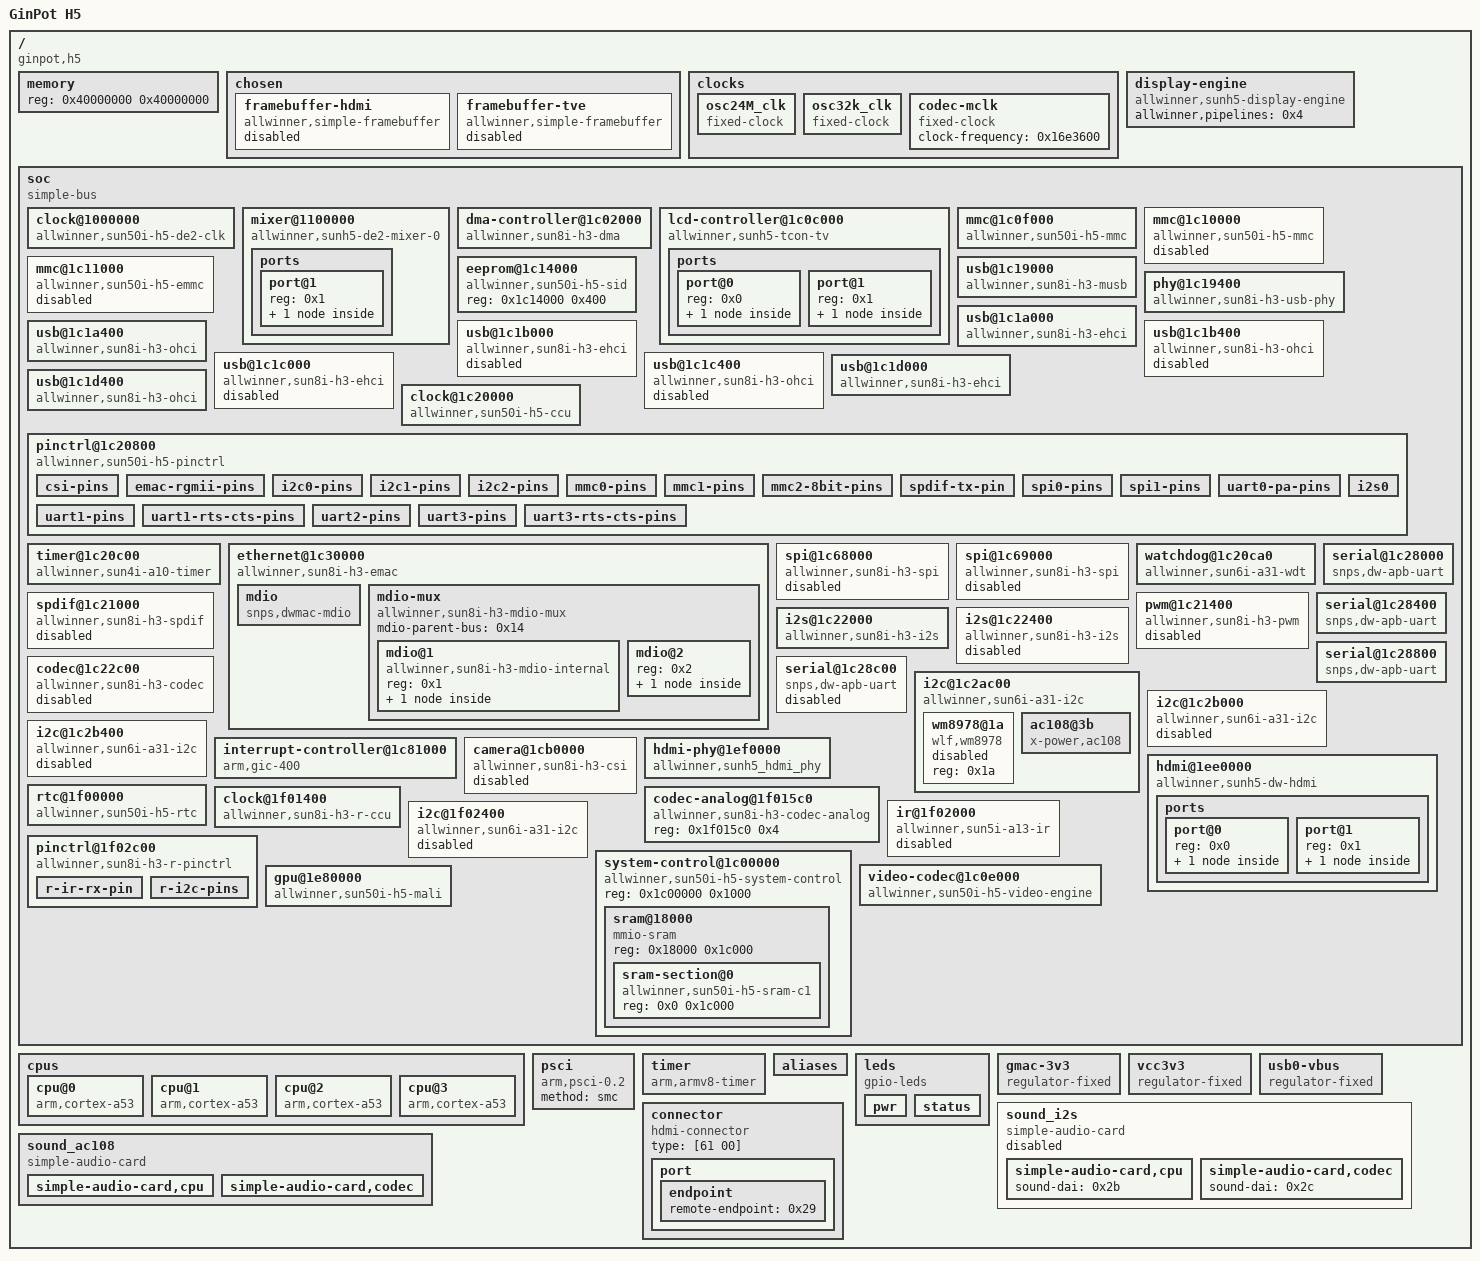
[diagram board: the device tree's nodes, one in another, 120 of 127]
/dts-v1/;

/ {
	serial-number = "82800001872ec2e4";
	interrupt-parent = <0x1>;
	#address-cells = <0x1>;
	#size-cells = <0x1>;
	model = "GinPot H5";
	compatible = "ginpot,h5", "allwinner,sun50i-h5";

	memory {
		reg = <0x40000000 0x40000000>;
		device_type = "memory";
	};

	chosen {
		linux,stdout-path = "/soc@01c00000/serial@01c28000:115200";
		bootargs = "console=ttyS0,115200 earlyprintk root=/dev/mmcblk0p2 rootfstype=ext4 rw rootwait panic=10 snd_soc_ac108.dyndbg=+p ac108_card.dyndbg=+p sunh5_drm.dyndbg=+p sunh5_mixer.dyndbg=+p sunh5_tcon.dyndbg=+p sunh5_drm_hdmi.dyndbg=+p";
		#address-cells = <0x1>;
		#size-cells = <0x1>;
		ranges;
		stdout-path = "serial0:115200n8";

		framebuffer-hdmi {
			compatible = "allwinner,simple-framebuffer", "simple-framebuffer";
			allwinner,pipeline = "mixer0-lcd0-hdmi";
			clocks = <0x2 0x6 0x3 0x66 0x3 0x6f>;
			status = "disabled";
		};

		framebuffer-tve {
			compatible = "allwinner,simple-framebuffer", "simple-framebuffer";
			allwinner,pipeline = "mixer1-lcd1-tve";
			clocks = <0x2 0x7 0x3 0x67>;
			status = "disabled";
		};
	};

	clocks {
		#address-cells = <0x1>;
		#size-cells = <0x1>;
		ranges;

		osc24M_clk {
			#clock-cells = <0x0>;
			compatible = "fixed-clock";
			clock-frequency = <0x16e3600>;
			clock-accuracy = <0xc350>;
			clock-output-names = "osc24M";
			phandle = <0xe>;
		};

		osc32k_clk {
			#clock-cells = <0x0>;
			compatible = "fixed-clock";
			clock-frequency = <0x8000>;
			clock-accuracy = <0xc350>;
			clock-output-names = "ext_osc32k";
			phandle = <0x24>;
		};

		codec-mclk {
			compatible = "fixed-clock";
			#clock-cells = <0x0>;
			clock-frequency = <0x16e3600>;
			phandle = <0x2f>;
		};
	};

	display-engine {
		compatible = "allwinner,sunh5-display-engine";
		allwinner,pipelines = <0x4>;
		status = "okay";
	};

	soc {
		compatible = "simple-bus";
		#address-cells = <0x1>;
		#size-cells = <0x1>;
		ranges;

		clock@1000000 {
			reg = <0x1000000 0x100000>;
			clocks = <0x3 0x65 0x3 0x30>;
			clock-names = "mod", "bus";
			resets = <0x3 0x22>;
			#clock-cells = <0x1>;
			#reset-cells = <0x1>;
			compatible = "allwinner,sun50i-h5-de2-clk";
			phandle = <0x2>;
		};

		mixer@1100000 {
			compatible = "allwinner,sunh5-de2-mixer-0";
			reg = <0x1100000 0x100000>;
			clocks = <0x2 0x0 0x2 0x6>;
			clock-names = "bus", "mod";
			resets = <0x2 0x0>;
			status = "okay";
			phandle = <0x4>;

			ports {
				#address-cells = <0x1>;
				#size-cells = <0x0>;

				port@1 {
					reg = <0x1>;

					endpoint {
						remote-endpoint = <0x5>;
						phandle = <0x6>;
					};
				};
			};
		};

		dma-controller@1c02000 {
			compatible = "allwinner,sun8i-h3-dma";
			reg = <0x1c02000 0x1000>;
			interrupts = <0x0 0x32 0x4>;
			clocks = <0x3 0x15>;
			resets = <0x3 0x6>;
			#dma-cells = <0x1>;
			phandle = <0x15>;
		};

		lcd-controller@1c0c000 {
			compatible = "allwinner,sunh5-tcon-tv";
			reg = <0x1c0c000 0x1000>;
			interrupts = <0x0 0x56 0x4>;
			clocks = <0x3 0x2a 0x3 0x66>;
			clock-names = "ahb", "tcon-ch1";
			resets = <0x3 0x1b>;
			reset-names = "lcd";
			status = "okay";

			ports {
				#address-cells = <0x1>;
				#size-cells = <0x0>;

				port@0 {
					reg = <0x0>;

					endpoint {
						remote-endpoint = <0x6>;
						phandle = <0x5>;
					};
				};

				port@1 {
					#address-cells = <0x1>;
					#size-cells = <0x0>;
					reg = <0x1>;

					endpoint@1 {
						reg = <0x1>;
						remote-endpoint = <0x7>;
						phandle = <0x22>;
					};
				};
			};
		};

		mmc@1c0f000 {
			reg = <0x1c0f000 0x1000>;
			pinctrl-names = "default";
			pinctrl-0 = <0x8>;
			resets = <0x3 0x7>;
			reset-names = "ahb";
			interrupts = <0x0 0x3c 0x4>;
			status = "okay";
			#address-cells = <0x1>;
			#size-cells = <0x0>;
			compatible = "allwinner,sun50i-h5-mmc", "allwinner,sun50i-a64-mmc";
			clocks = <0x3 0x16 0x3 0x47>;
			clock-names = "ahb", "mmc";
			vmmc-supply = <0x9>;
			bus-width = <0x4>;
			cd-gpios = <0xa 0x5 0x6 0x1>;
		};

		mmc@1c10000 {
			reg = <0x1c10000 0x1000>;
			pinctrl-names = "default";
			pinctrl-0 = <0xb>;
			resets = <0x3 0x8>;
			reset-names = "ahb";
			interrupts = <0x0 0x3d 0x4>;
			status = "disabled";
			#address-cells = <0x1>;
			#size-cells = <0x0>;
			compatible = "allwinner,sun50i-h5-mmc", "allwinner,sun50i-a64-mmc";
			clocks = <0x3 0x17 0x3 0x4a>;
			clock-names = "ahb", "mmc";
		};

		mmc@1c11000 {
			reg = <0x1c11000 0x1000>;
			resets = <0x3 0x9>;
			reset-names = "ahb";
			interrupts = <0x0 0x3e 0x4>;
			status = "disabled";
			#address-cells = <0x1>;
			#size-cells = <0x0>;
			compatible = "allwinner,sun50i-h5-emmc", "allwinner,sun50i-a64-emmc";
			clocks = <0x3 0x18 0x3 0x4d>;
			clock-names = "ahb", "mmc";
		};

		eeprom@1c14000 {
			reg = <0x1c14000 0x400>;
			compatible = "allwinner,sun50i-h5-sid";
		};

		usb@1c19000 {
			compatible = "allwinner,sun8i-h3-musb";
			reg = <0x1c19000 0x400>;
			clocks = <0x3 0x20>;
			resets = <0x3 0x11>;
			interrupts = <0x0 0x47 0x4>;
			interrupt-names = "mc";
			phys = <0xc 0x0>;
			phy-names = "usb";
			extcon = <0xc 0x0>;
			dr_mode = "otg";
			status = "okay";
		};

		phy@1c19400 {
			compatible = "allwinner,sun8i-h3-usb-phy";
			reg = <0x1c19400 0x2c 0x1c1a800 0x4 0x1c1b800 0x4 0x1c1c800 0x4 0x1c1d800 0x4>;
			reg-names = "phy_ctrl", "pmu0", "pmu1", "pmu2", "pmu3";
			clocks = <0x3 0x58 0x3 0x59 0x3 0x5a 0x3 0x5b>;
			clock-names = "usb0_phy", "usb1_phy", "usb2_phy", "usb3_phy";
			resets = <0x3 0x0 0x3 0x1 0x3 0x2 0x3 0x3>;
			reset-names = "usb0_reset", "usb1_reset", "usb2_reset", "usb3_reset";
			status = "okay";
			#phy-cells = <0x1>;
			usb0_id_det-gpios = <0xa 0x6 0xc 0x0>;
			usb0_vbus-supply = <0xd>;
			phandle = <0xc>;
		};

		usb@1c1a000 {
			compatible = "allwinner,sun8i-h3-ehci", "generic-ehci";
			reg = <0x1c1a000 0x100>;
			interrupts = <0x0 0x48 0x4>;
			clocks = <0x3 0x21 0x3 0x25>;
			resets = <0x3 0x12 0x3 0x16>;
			status = "okay";
		};

		usb@1c1a400 {
			compatible = "allwinner,sun8i-h3-ohci", "generic-ohci";
			reg = <0x1c1a400 0x100>;
			interrupts = <0x0 0x49 0x4>;
			clocks = <0x3 0x21 0x3 0x25 0x3 0x5c>;
			resets = <0x3 0x12 0x3 0x16>;
			status = "okay";
		};

		usb@1c1b000 {
			compatible = "allwinner,sun8i-h3-ehci", "generic-ehci";
			reg = <0x1c1b000 0x100>;
			interrupts = <0x0 0x4a 0x4>;
			clocks = <0x3 0x22 0x3 0x26>;
			resets = <0x3 0x13 0x3 0x17>;
			phys = <0xc 0x1>;
			status = "disabled";
		};

		usb@1c1b400 {
			compatible = "allwinner,sun8i-h3-ohci", "generic-ohci";
			reg = <0x1c1b400 0x100>;
			interrupts = <0x0 0x4b 0x4>;
			clocks = <0x3 0x22 0x3 0x26 0x3 0x5d>;
			resets = <0x3 0x13 0x3 0x17>;
			phys = <0xc 0x1>;
			status = "disabled";
		};

		usb@1c1c000 {
			compatible = "allwinner,sun8i-h3-ehci", "generic-ehci";
			reg = <0x1c1c000 0x100>;
			interrupts = <0x0 0x4c 0x4>;
			clocks = <0x3 0x23 0x3 0x27>;
			resets = <0x3 0x14 0x3 0x18>;
			phys = <0xc 0x2>;
			status = "disabled";
		};

		usb@1c1c400 {
			compatible = "allwinner,sun8i-h3-ohci", "generic-ohci";
			reg = <0x1c1c400 0x100>;
			interrupts = <0x0 0x4d 0x4>;
			clocks = <0x3 0x23 0x3 0x27 0x3 0x5e>;
			resets = <0x3 0x14 0x3 0x18>;
			phys = <0xc 0x2>;
			status = "disabled";
		};

		usb@1c1d000 {
			compatible = "allwinner,sun8i-h3-ehci", "generic-ehci";
			reg = <0x1c1d000 0x100>;
			interrupts = <0x0 0x4e 0x4>;
			clocks = <0x3 0x24 0x3 0x28>;
			resets = <0x3 0x15 0x3 0x19>;
			phys = <0xc 0x3>;
			status = "okay";
		};

		usb@1c1d400 {
			compatible = "allwinner,sun8i-h3-ohci", "generic-ohci";
			reg = <0x1c1d400 0x100>;
			interrupts = <0x0 0x4f 0x4>;
			clocks = <0x3 0x24 0x3 0x28 0x3 0x5f>;
			resets = <0x3 0x15 0x3 0x19>;
			phys = <0xc 0x3>;
			status = "okay";
		};

		clock@1c20000 {
			reg = <0x1c20000 0x400>;
			clocks = <0xe 0xf 0x0>;
			clock-names = "hosc", "losc";
			#clock-cells = <0x1>;
			#reset-cells = <0x1>;
			compatible = "allwinner,sun50i-h5-ccu";
			phandle = <0x3>;
		};

		pinctrl@1c20800 {
			reg = <0x1c20800 0x400>;
			interrupts = <0x0 0xb 0x4 0x0 0x11 0x4 0x0 0x17 0x4>;
			clocks = <0x3 0x36 0xe 0xf 0x0>;
			clock-names = "apb", "hosc", "losc";
			gpio-controller;
			#gpio-cells = <0x3>;
			interrupt-controller;
			#interrupt-cells = <0x3>;
			compatible = "allwinner,sun50i-h5-pinctrl";
			phandle = <0xa>;

			csi-pins {
				pins = "PE0", "PE2", "PE3", "PE4", "PE5", "PE6", "PE7", "PE8", "PE9", "PE10", "PE11";
				function = "csi";
				phandle = <0x20>;
			};

			emac-rgmii-pins {
				pins = "PD0", "PD1", "PD2", "PD3", "PD4", "PD5", "PD7", "PD8", "PD9", "PD10", "PD12", "PD13", "PD15", "PD16", "PD17";
				function = "emac";
				drive-strength = <0x28>;
				phandle = <0x11>;
			};

			i2c0-pins {
				pins = "PA11", "PA12";
				function = "i2c0";
				phandle = <0x1d>;
			};

			i2c1-pins {
				pins = "PA18", "PA19";
				function = "i2c1";
				phandle = <0x1e>;
			};

			i2c2-pins {
				pins = "PE12", "PE13";
				function = "i2c2";
				phandle = <0x1f>;
			};

			mmc0-pins {
				pins = "PF0", "PF1", "PF2", "PF3", "PF4", "PF5";
				function = "mmc0";
				drive-strength = <0x1e>;
				bias-pull-up;
				phandle = <0x8>;
			};

			mmc1-pins {
				pins = "PG0", "PG1", "PG2", "PG3", "PG4", "PG5";
				function = "mmc1";
				drive-strength = <0x1e>;
				bias-pull-up;
				phandle = <0xb>;
			};

			mmc2-8bit-pins {
				pins = "PC5", "PC6", "PC8", "PC9", "PC10", "PC11", "PC12", "PC13", "PC14", "PC15", "PC16";
				function = "mmc2";
				drive-strength = <0x1e>;
				bias-pull-up;
			};

			spdif-tx-pin {
				pins = "PA17";
				function = "spdif";
			};

			spi0-pins {
				pins = "PC0", "PC1", "PC2", "PC3";
				function = "spi0";
				phandle = <0x16>;
			};

			spi1-pins {
				pins = "PA15", "PA16", "PA14", "PA13";
				function = "spi1";
				phandle = <0x17>;
			};

			uart0-pa-pins {
				pins = "PA4", "PA5";
				function = "uart0";
				phandle = <0x1a>;
			};

			uart1-pins {
				pins = "PG6", "PG7";
				function = "uart1";
				phandle = <0x1b>;
			};

			uart1-rts-cts-pins {
				pins = "PG8", "PG9";
				function = "uart1";
			};

			uart2-pins {
				pins = "PA0", "PA1";
				function = "uart2";
				phandle = <0x1c>;
			};

			uart3-pins {
				pins = "PA13", "PA14";
				function = "uart3";
			};

			uart3-rts-cts-pins {
				pins = "PA15", "PA16";
				function = "uart3";
			};

			i2s0 {
				pins = "PA18", "PA19", "PA20", "PA21";
				function = "i2s0";
				phandle = <0x18>;
			};
		};

		timer@1c20c00 {
			compatible = "allwinner,sun4i-a10-timer";
			reg = <0x1c20c00 0xa0>;
			interrupts = <0x0 0x12 0x4 0x0 0x13 0x4>;
			clocks = <0xe>;
		};

		ethernet@1c30000 {
			local-mac-address = [02 01 87 2e c2 e4];
			compatible = "allwinner,sun8i-h3-emac";
			syscon = <0x10>;
			reg = <0x1c30000 0x10000>;
			interrupts = <0x0 0x52 0x4>;
			interrupt-names = "macirq";
			resets = <0x3 0xc>;
			reset-names = "stmmaceth";
			clocks = <0x3 0x1b>;
			clock-names = "stmmaceth";
			status = "okay";
			pinctrl-names = "default";
			pinctrl-0 = <0x11>;
			phy-supply = <0x12>;
			phy-handle = <0x13>;
			phy-mode = "rgmii";

			mdio {
				#address-cells = <0x1>;
				#size-cells = <0x0>;
				compatible = "snps,dwmac-mdio";
				phandle = <0x14>;
			};

			mdio-mux {
				compatible = "allwinner,sun8i-h3-mdio-mux";
				#address-cells = <0x1>;
				#size-cells = <0x0>;
				mdio-parent-bus = <0x14>;

				mdio@1 {
					compatible = "allwinner,sun8i-h3-mdio-internal";
					reg = <0x1>;
					#address-cells = <0x1>;
					#size-cells = <0x0>;

					ethernet-phy@1 {
						compatible = "ethernet-phy-ieee802.3-c22";
						reg = <0x1>;
						clocks = <0x3 0x43>;
						resets = <0x3 0x27>;
					};
				};

				mdio@2 {
					reg = <0x2>;
					#address-cells = <0x1>;
					#size-cells = <0x0>;

					ethernet-phy@7 {
						compatible = "ethernet-phy-ieee802.3-c22";
						reg = <0x7>;
						phandle = <0x13>;
					};
				};
			};
		};

		spi@1c68000 {
			compatible = "allwinner,sun8i-h3-spi";
			reg = <0x1c68000 0x1000>;
			interrupts = <0x0 0x41 0x4>;
			clocks = <0x3 0x1e 0x3 0x52>;
			clock-names = "ahb", "mod";
			dmas = <0x15 0x17 0x15 0x17>;
			dma-names = "rx", "tx";
			pinctrl-names = "default";
			pinctrl-0 = <0x16>;
			resets = <0x3 0xf>;
			status = "disabled";
			#address-cells = <0x1>;
			#size-cells = <0x0>;
		};

		spi@1c69000 {
			compatible = "allwinner,sun8i-h3-spi";
			reg = <0x1c69000 0x1000>;
			interrupts = <0x0 0x42 0x4>;
			clocks = <0x3 0x1f 0x3 0x53>;
			clock-names = "ahb", "mod";
			dmas = <0x15 0x18 0x15 0x18>;
			dma-names = "rx", "tx";
			pinctrl-names = "default";
			pinctrl-0 = <0x17>;
			resets = <0x3 0x10>;
			status = "disabled";
			#address-cells = <0x1>;
			#size-cells = <0x0>;
		};

		watchdog@1c20ca0 {
			compatible = "allwinner,sun6i-a31-wdt";
			reg = <0x1c20ca0 0x20>;
			interrupts = <0x0 0x19 0x4>;
		};

		spdif@1c21000 {
			#sound-dai-cells = <0x0>;
			compatible = "allwinner,sun8i-h3-spdif";
			reg = <0x1c21000 0x400>;
			interrupts = <0x0 0xc 0x4>;
			clocks = <0x3 0x35 0x3 0x57>;
			resets = <0x3 0x29>;
			clock-names = "apb", "spdif";
			dmas = <0x15 0x2>;
			dma-names = "tx";
			status = "disabled";
		};

		pwm@1c21400 {
			compatible = "allwinner,sun8i-h3-pwm";
			reg = <0x1c21400 0x8>;
			clocks = <0xe>;
			#pwm-cells = <0x3>;
			status = "disabled";
		};

		i2s@1c22000 {
			#sound-dai-cells = <0x0>;
			compatible = "allwinner,sun8i-h3-i2s";
			reg = <0x1c22000 0x400>;
			interrupts = <0x0 0xd 0x4>;
			clocks = <0x3 0x38 0x3 0x54>;
			clock-names = "apb", "mod";
			dmas = <0x15 0x3 0x15 0x3>;
			resets = <0x3 0x2b>;
			dma-names = "rx", "tx";
			status = "okay";
			pinctrl-names = "default";
			pinctrl-0 = <0x18>;
			#address-cells = <0x1>;
			#size-cells = <0x0>;
			phandle = <0x2b>;
		};

		i2s@1c22400 {
			#sound-dai-cells = <0x0>;
			compatible = "allwinner,sun8i-h3-i2s";
			reg = <0x1c22400 0x400>;
			interrupts = <0x0 0xe 0x4>;
			clocks = <0x3 0x39 0x3 0x55>;
			clock-names = "apb", "mod";
			dmas = <0x15 0x4 0x15 0x4>;
			resets = <0x3 0x2c>;
			dma-names = "rx", "tx";
			status = "disabled";
		};

		codec@1c22c00 {
			#sound-dai-cells = <0x0>;
			compatible = "allwinner,sun8i-h3-codec";
			reg = <0x1c22c00 0x400>;
			interrupts = <0x0 0x1d 0x4>;
			clocks = <0x3 0x34 0x3 0x6d>;
			clock-names = "apb", "codec";
			resets = <0x3 0x28>;
			dmas = <0x15 0xf 0x15 0xf>;
			dma-names = "rx", "tx";
			allwinner,codec-analog-controls = <0x19>;
			status = "disabled";
			allwinner,audio-routing = "Line Out", "LINEOUT", "MIC1", "Mic", "Mic", "MBIAS";
		};

		serial@1c28000 {
			compatible = "snps,dw-apb-uart";
			reg = <0x1c28000 0x400>;
			interrupts = <0x0 0x0 0x4>;
			reg-shift = <0x2>;
			reg-io-width = <0x4>;
			clocks = <0x3 0x3e>;
			resets = <0x3 0x31>;
			dmas = <0x15 0x6 0x15 0x6>;
			dma-names = "rx", "tx";
			status = "okay";
			pinctrl-names = "default";
			pinctrl-0 = <0x1a>;
		};

		serial@1c28400 {
			compatible = "snps,dw-apb-uart";
			reg = <0x1c28400 0x400>;
			interrupts = <0x0 0x1 0x4>;
			reg-shift = <0x2>;
			reg-io-width = <0x4>;
			clocks = <0x3 0x3f>;
			resets = <0x3 0x32>;
			dmas = <0x15 0x7 0x15 0x7>;
			dma-names = "rx", "tx";
			status = "okay";
			pinctrl-names = "default";
			pinctrl-0 = <0x1b>;
		};

		serial@1c28800 {
			compatible = "snps,dw-apb-uart";
			reg = <0x1c28800 0x400>;
			interrupts = <0x0 0x2 0x4>;
			reg-shift = <0x2>;
			reg-io-width = <0x4>;
			clocks = <0x3 0x40>;
			resets = <0x3 0x33>;
			dmas = <0x15 0x8 0x15 0x8>;
			dma-names = "rx", "tx";
			status = "okay";
			pinctrl-names = "default";
			pinctrl-0 = <0x1c>;
		};

		serial@1c28c00 {
			compatible = "snps,dw-apb-uart";
			reg = <0x1c28c00 0x400>;
			interrupts = <0x0 0x3 0x4>;
			reg-shift = <0x2>;
			reg-io-width = <0x4>;
			clocks = <0x3 0x41>;
			resets = <0x3 0x34>;
			dmas = <0x15 0x9 0x15 0x9>;
			dma-names = "rx", "tx";
			status = "disabled";
		};

		i2c@1c2ac00 {
			compatible = "allwinner,sun6i-a31-i2c";
			reg = <0x1c2ac00 0x400>;
			interrupts = <0x0 0x6 0x4>;
			clocks = <0x3 0x3b>;
			resets = <0x3 0x2e>;
			pinctrl-names = "default";
			pinctrl-0 = <0x1d>;
			status = "okay";
			#address-cells = <0x1>;
			#size-cells = <0x0>;

			wm8978@1a {
				compatible = "wlf,wm8978";
				reg = <0x1a>;
				#sound-dai-cells = <0x0>;
				status = "disabled";
				phandle = <0x2c>;
			};

			ac108@3b {
				compatible = "x-power,ac108";
				reg = <0x3b>;
				#sound-dai-cells = <0x0>;
				data-protocol = <0x0>;
				phandle = <0x2e>;
			};
		};

		i2c@1c2b000 {
			compatible = "allwinner,sun6i-a31-i2c";
			reg = <0x1c2b000 0x400>;
			interrupts = <0x0 0x7 0x4>;
			clocks = <0x3 0x3c>;
			resets = <0x3 0x2f>;
			pinctrl-names = "default";
			pinctrl-0 = <0x1e>;
			status = "disabled";
			#address-cells = <0x1>;
			#size-cells = <0x0>;
		};

		i2c@1c2b400 {
			compatible = "allwinner,sun6i-a31-i2c";
			reg = <0x1c2b400 0x400>;
			interrupts = <0x0 0x8 0x4>;
			clocks = <0x3 0x3d>;
			resets = <0x3 0x30>;
			pinctrl-names = "default";
			pinctrl-0 = <0x1f>;
			status = "disabled";
			#address-cells = <0x1>;
			#size-cells = <0x0>;
		};

		interrupt-controller@1c81000 {
			compatible = "arm,gic-400";
			reg = <0x1c81000 0x1000 0x1c82000 0x2000 0x1c84000 0x2000 0x1c86000 0x2000>;
			interrupt-controller;
			#interrupt-cells = <0x3>;
			interrupts = <0x1 0x9 0xf04>;
			phandle = <0x1>;
		};

		camera@1cb0000 {
			compatible = "allwinner,sun8i-h3-csi";
			reg = <0x1cb0000 0x1000>;
			interrupts = <0x0 0x54 0x4>;
			clocks = <0x3 0x2d 0x3 0x6a 0x3 0x62>;
			clock-names = "bus", "mod", "ram";
			resets = <0x3 0x1e>;
			pinctrl-names = "default";
			pinctrl-0 = <0x20>;
			status = "disabled";
		};

		hdmi@1ee0000 {
			compatible = "allwinner,sunh5-dw-hdmi";
			reg = <0x1ee0000 0x10000>;
			reg-io-width = <0x1>;
			interrupts = <0x0 0x58 0x4>;
			clocks = <0x3 0x2f 0x3 0x70 0x3 0x6f>;
			clock-names = "iahb", "isfr", "tmds";
			resets = <0x3 0x21>;
			reset-names = "ctrl";
			phys = <0x21>;
			phy-names = "hdmi-phy";
			status = "okay";

			ports {
				#address-cells = <0x1>;
				#size-cells = <0x0>;

				port@0 {
					reg = <0x0>;

					endpoint {
						remote-endpoint = <0x22>;
						phandle = <0x7>;
					};
				};

				port@1 {
					reg = <0x1>;

					endpoint {
						remote-endpoint = <0x23>;
						phandle = <0x29>;
					};
				};
			};
		};

		hdmi-phy@1ef0000 {
			compatible = "allwinner,sunh5_hdmi_phy";
			reg = <0x1ef0000 0x10000>;
			clocks = <0x3 0x2f 0x3 0x70 0x3 0x6>;
			clock-names = "bus", "mod", "pll-0";
			resets = <0x3 0x20>;
			reset-names = "phy";
			#phy-cells = <0x0>;
			status = "okay";
			phandle = <0x21>;
		};

		rtc@1f00000 {
			reg = <0x1f00000 0x400>;
			interrupts = <0x0 0x28 0x4 0x0 0x29 0x4>;
			clock-output-names = "osc32k", "osc32k-out", "iosc";
			clocks = <0x24>;
			#clock-cells = <0x1>;
			compatible = "allwinner,sun50i-h5-rtc";
			phandle = <0xf>;
		};

		clock@1f01400 {
			compatible = "allwinner,sun8i-h3-r-ccu";
			reg = <0x1f01400 0x100>;
			clocks = <0xe 0xf 0x0 0xf 0x2 0x3 0x9>;
			clock-names = "hosc", "losc", "iosc", "pll-periph";
			#clock-cells = <0x1>;
			#reset-cells = <0x1>;
			phandle = <0x25>;
		};

		codec-analog@1f015c0 {
			compatible = "allwinner,sun8i-h3-codec-analog";
			reg = <0x1f015c0 0x4>;
			phandle = <0x19>;
		};

		ir@1f02000 {
			compatible = "allwinner,sun5i-a13-ir";
			clocks = <0x25 0x4 0x25 0xb>;
			clock-names = "apb", "ir";
			resets = <0x25 0x0>;
			interrupts = <0x0 0x25 0x4>;
			reg = <0x1f02000 0x400>;
			status = "disabled";
		};

		i2c@1f02400 {
			compatible = "allwinner,sun6i-a31-i2c";
			reg = <0x1f02400 0x400>;
			interrupts = <0x0 0x2c 0x4>;
			pinctrl-names = "default";
			pinctrl-0 = <0x26>;
			clocks = <0x25 0x9>;
			resets = <0x25 0x5>;
			status = "disabled";
			#address-cells = <0x1>;
			#size-cells = <0x0>;
		};

		pinctrl@1f02c00 {
			compatible = "allwinner,sun8i-h3-r-pinctrl";
			reg = <0x1f02c00 0x400>;
			interrupts = <0x0 0x2d 0x4>;
			clocks = <0x25 0x3 0xe 0xf 0x0>;
			clock-names = "apb", "hosc", "losc";
			gpio-controller;
			#gpio-cells = <0x3>;
			interrupt-controller;
			#interrupt-cells = <0x3>;
			phandle = <0x28>;

			r-ir-rx-pin {
				pins = "PL11";
				function = "s_cir_rx";
			};

			r-i2c-pins {
				pins = "PL0", "PL1";
				function = "s_i2c";
				phandle = <0x26>;
			};
		};

		system-control@1c00000 {
			compatible = "allwinner,sun50i-h5-system-control";
			reg = <0x1c00000 0x1000>;
			#address-cells = <0x1>;
			#size-cells = <0x1>;
			ranges;
			phandle = <0x10>;

			sram@18000 {
				compatible = "mmio-sram";
				reg = <0x18000 0x1c000>;
				#address-cells = <0x1>;
				#size-cells = <0x1>;
				ranges = <0x0 0x18000 0x1c000>;

				sram-section@0 {
					compatible = "allwinner,sun50i-h5-sram-c1", "allwinner,sun4i-a10-sram-c1";
					reg = <0x0 0x1c000>;
					phandle = <0x27>;
				};
			};
		};

		video-codec@1c0e000 {
			compatible = "allwinner,sun50i-h5-video-engine";
			reg = <0x1c0e000 0x1000>;
			clocks = <0x3 0x29 0x3 0x6c 0x3 0x61>;
			clock-names = "ahb", "mod", "ram";
			resets = <0x3 0x1a>;
			interrupts = <0x0 0x3a 0x4>;
			allwinner,sram = <0x27 0x1>;
		};

		gpu@1e80000 {
			compatible = "allwinner,sun50i-h5-mali", "arm,mali-450";
			reg = <0x1e80000 0x30000>;
			interrupts = <0x0 0x60 0x4 0x0 0x61 0x4 0x0 0x63 0x4 0x0 0x64 0x4 0x0 0x65 0x4 0x0 0x66 0x4 0x0 0x67 0x4 0x0 0x68 0x4 0x0 0x69 0x4 0x0 0x6a 0x4 0x0 0x6b 0x4 0x0 0x62 0x4>;
			interrupt-names = "gp", "gpmmu", "pp", "pp0", "ppmmu0", "pp1", "ppmmu1", "pp2", "ppmmu2", "pp3", "ppmmu3", "pmu";
			clocks = <0x3 0x31 0x3 0x72>;
			clock-names = "bus", "core";
			resets = <0x3 0x23>;
			assigned-clocks = <0x3 0x72>;
			assigned-clock-rates = <0x16e36000>;
		};
	};

	cpus {
		#address-cells = <0x1>;
		#size-cells = <0x0>;

		cpu@0 {
			compatible = "arm,cortex-a53";
			device_type = "cpu";
			reg = <0x0>;
			enable-method = "psci";
		};

		cpu@1 {
			compatible = "arm,cortex-a53";
			device_type = "cpu";
			reg = <0x1>;
			enable-method = "psci";
		};

		cpu@2 {
			compatible = "arm,cortex-a53";
			device_type = "cpu";
			reg = <0x2>;
			enable-method = "psci";
		};

		cpu@3 {
			compatible = "arm,cortex-a53";
			device_type = "cpu";
			reg = <0x3>;
			enable-method = "psci";
		};
	};

	psci {
		compatible = "arm,psci-0.2";
		method = "smc";
	};

	timer {
		compatible = "arm,armv8-timer";
		interrupts = <0x1 0xd 0xf08 0x1 0xe 0xf08 0x1 0xb 0xf08 0x1 0xa 0xf08>;
	};

	aliases {
		ethernet0 = "/soc/ethernet@1c30000";
		serial0 = "/soc/serial@1c28000";
		i2c0 = "/soc/i2c@1c2ac00";
	};

	leds {
		compatible = "gpio-leds";

		pwr {
			label = "nanopi:green:pwr";
			gpios = <0x28 0x0 0xa 0x0>;
			default-state = "on";
		};

		status {
			label = "nanopi:blue:status";
			gpios = <0xa 0x0 0xa 0x0>;
			linux,default-trigger = "heartbeat";
		};
	};

	gmac-3v3 {
		compatible = "regulator-fixed";
		regulator-name = "gmac-3v3";
		regulator-min-microvolt = <0x325aa0>;
		regulator-max-microvolt = <0x325aa0>;
		startup-delay-us = <0x186a0>;
		enable-active-high;
		gpio = <0xa 0x3 0x6 0x0>;
		phandle = <0x12>;
	};

	vcc3v3 {
		compatible = "regulator-fixed";
		regulator-name = "vcc3v3";
		regulator-min-microvolt = <0x325aa0>;
		regulator-max-microvolt = <0x325aa0>;
		phandle = <0x9>;
	};

	usb0-vbus {
		compatible = "regulator-fixed";
		regulator-name = "usb0-vbus";
		regulator-min-microvolt = <0x4c4b40>;
		regulator-max-microvolt = <0x4c4b40>;
		enable-active-high;
		gpio = <0x28 0x0 0x2 0x0>;
		status = "okay";
		phandle = <0xd>;
	};

	connector {
		compatible = "hdmi-connector";
		type = [61 00];

		port {

			endpoint {
				remote-endpoint = <0x29>;
				phandle = <0x23>;
			};
		};
	};

	sound_i2s {
		compatible = "simple-audio-card";
		simple-audio-card,name = "WM8978";
		simple-audio-card,mclk-fs = <0x100>;
		simple-audio-card,format = "i2s";
		simple-audio-card,bitclock-master = <0x2a>;
		simple-audio-card,frame-master = <0x2a>;
		status = "disabled";

		simple-audio-card,cpu {
			sound-dai = <0x2b>;
			phandle = <0x2a>;
		};

		simple-audio-card,codec {
			sound-dai = <0x2c>;
		};
	};

	sound_ac108 {
		compatible = "simple-audio-card";
		simple-audio-card,name = "ac108-card";
		simple-audio-card,format = "dsp_a";
		simple-audio-card,mclk-fs = <0x200>;
		simple-audio-card,bitclock-master = <0x2d>;
		simple-audio-card,frame-master = <0x2d>;
		simple-audio-card,channels-playback-override = <0x4>;
		simple-audio-card,channels-capture-override = <0x4>;
		status = "okay";

		simple-audio-card,cpu {
			sound-dai = <0x2b>;
			dai-tdm-slot-num = <0x4>;
			dai-tdm-slot-width = <0x20>;
			dai-tdm-slot-tx-mask = <0x1 0x1 0x1 0x1>;
			dai-tdm-slot-rx-mask = <0x1 0x1 0x1 0x1>;
			phandle = <0x2d>;
		};

		simple-audio-card,codec {
			sound-dai = <0x2e>;
			clocks = <0x2f>;
		};
	};
};
